VERSION ""

NS_ :

BS_:

BU_: XXX

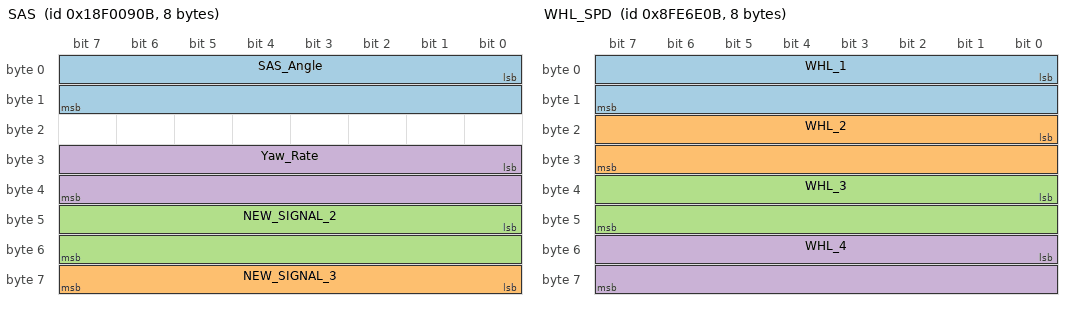
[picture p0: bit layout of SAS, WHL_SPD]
BO_ 418384139 SAS: 8 XXX
 SG_ SAS_Angle : 0|16@1+ (1,0) [-3276.8|3276.7] "Deg" XXX
 SG_ NEW_SIGNAL_3 : 56|8@1+ (1,0) [0|255] "" XXX
 SG_ NEW_SIGNAL_2 : 40|16@1+ (0.01,0) [0|255] "" XXX
 SG_ Yaw_Rate : 24|16@1+ (0.01,-321.13) [0|63] "deg/s" XXX

BO_ 218095872 POSEMS: 8 XXX
 SG_ NEW_SIGNAL_1 : 8|16@1+ (1,0) [0|7] "" XXX
 SG_ NEW_SIGNAL_2 : 24|16@1+ (1,0) [0|8191] "" XXX

BO_ 217056256 NEW_MSG_1: 8 XXX
 SG_ NEW_SIGNAL_1 : 19|12@0+ (1,0) [0|255] "" XXX

BO_ 150892043 WHL_SPD: 8 XXX
 SG_ WHL_1 : 0|16@1+ (1,0) [0|255] "" XXX
 SG_ WHL_2 : 16|16@1+ (1,0) [0|7] "" XXX
 SG_ WHL_3 : 32|16@1+ (1,0) [0|7] "" XXX
 SG_ WHL_4 : 48|16@1+ (1,0) [0|7] "" XXX

BO_ 218097152 NEW_MSG_2: 8 XXX
 SG_ NEW_SIGNAL_1 : 7|8@0+ (1,0) [0|65535] "" XXX

BO_ 218096128 NEW_MSG_3: 8 XXX
 SG_ NEW_SIGNAL_1 : 47|16@0+ (1,0) [0|255] "" XXX
 SG_ NEW_SIGNAL_2 : 7|8@0+ (1,0) [0|255] "" XXX
